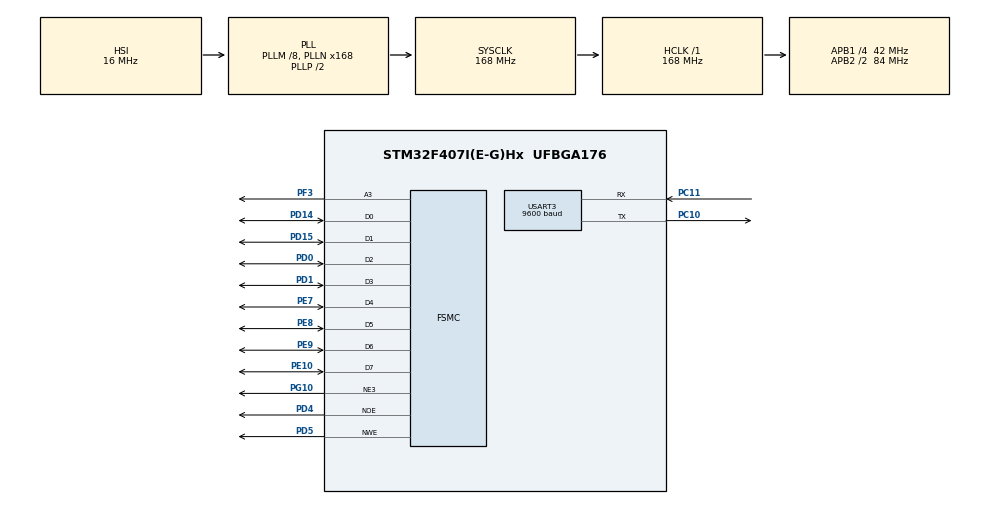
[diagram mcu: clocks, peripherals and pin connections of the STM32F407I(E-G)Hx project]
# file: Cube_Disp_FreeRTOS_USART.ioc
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FREERTOS.Tasks01=defaultTask,0,128,StartDefaultTask,Default,NULL,Dynamic,NULL,NULL
Mcu.Family=STM32F4
Mcu.Name=STM32F407I(E-G)Hx
Mcu.Package=UFBGA176
NVIC.PriorityGroup=NVIC_PRIORITYGROUP_4
NVIC.TIM1_UP_TIM10_IRQn=true\:0\:0\:false\:false\:true\:false\:false\:true
NVIC.TimeBase=TIM1_UP_TIM10_IRQn
NVIC.TimeBaseIP=TIM1
PC10.Mode=Asynchronous
PC10.Signal=USART3_TX
PC11.Mode=Asynchronous
PC11.Signal=USART3_RX
PD0.Signal=FSMC_D2_DA2
PD1.Signal=FSMC_D3_DA3
PD14.Signal=FSMC_D0_DA0
PD15.Signal=FSMC_D1_DA1
PD4.Signal=FSMC_NOE
PD5.Signal=FSMC_NWE
PE10.Signal=FSMC_D7_DA7
PE7.Signal=FSMC_D4_DA4
PE8.Signal=FSMC_D5_DA5
PE9.Signal=FSMC_D6_DA6
PF3.Signal=FSMC_A3
PG10.Mode=NorPsramChipSelect3_3
PG10.Signal=FSMC_NE3
ProjectManager.HeapSize=0x200
ProjectManager.StackSize=0x400
ProjectManager.TargetToolchain=SW4STM32
RCC.48MHZClocksFreq_Value=48000000
RCC.AHBFreq_Value=168000000
RCC.APB1CLKDivider=RCC_HCLK_DIV4
RCC.APB1Freq_Value=42000000
RCC.APB1TimFreq_Value=84000000
RCC.APB2CLKDivider=RCC_HCLK_DIV2
RCC.APB2Freq_Value=84000000
RCC.APB2TimFreq_Value=168000000
RCC.CortexFreq_Value=168000000
RCC.FLatency-AdvancedSettings=FLASH_LATENCY_5
RCC.HCLKFreq_Value=168000000
RCC.HSE_VALUE=25000000
RCC.HSI_VALUE=16000000
RCC.LSE_VALUE=32768
RCC.PLLM=8
RCC.PLLN=168
RCC.PLLQ=7
RCC.PWR_Regulator_Voltage_Scale-AdvancedSettings=PWR_REGULATOR_VOLTAGE_SCALE1
RCC.SYSCLKFreq_VALUE=168000000
RCC.SYSCLKSource=RCC_SYSCLKSOURCE_PLLCLK
RCC.VCOOutputFreq_Value=336000000
SH.FSMC_A3.0=FSMC_A3,A3_3
SH.FSMC_D0_DA0.0=FSMC_D0,8b-d3
SH.FSMC_D1_DA1.0=FSMC_D1,8b-d3
SH.FSMC_D2_DA2.0=FSMC_D2,8b-d3
SH.FSMC_D3_DA3.0=FSMC_D3,8b-d3
SH.FSMC_D4_DA4.0=FSMC_D4,8b-d3
SH.FSMC_D5_DA5.0=FSMC_D5,8b-d3
SH.FSMC_D6_DA6.0=FSMC_D6,8b-d3
SH.FSMC_D7_DA7.0=FSMC_D7,8b-d3
SH.FSMC_NOE.0=FSMC_NOE,Lcd3
SH.FSMC_NWE.0=FSMC_NWE,Lcd3
STMicroelectronics.X-CUBE-TOUCHGFX.4.13.0.ApplicationCcGraphicsJjApplication=TouchGFXOoGenerator
STMicroelectronics.X-CUBE-TOUCHGFX.4.13.0.tgfx_custom_height=240
STMicroelectronics.X-CUBE-TOUCHGFX.4.13.0.tgfx_custom_width=320
USART3.BaudRate=9600
USART3.Parity=PARITY_ODD
USART3.VirtualMode=VM_ASYNC
VP_CRC_VS_CRC.Mode=CRC_Activate
VP_FREERTOS_VS_CMSIS_V1.Mode=CMSIS_V1
VP_SYS_VS_tim1.Mode=TIM1
board=STM3240G-EVAL

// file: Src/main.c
/* USER CODE BEGIN Header */
/**
  ******************************************************************************
  * @file           : main.c
  * @brief          : Main program body
  ******************************************************************************
  * @attention
  *
  * <h2><center>&copy; Copyright (c) 2020 STMicroelectronics.
  * All rights reserved.</center></h2>
  *
  * This software component is licensed by ST under Ultimate Liberty license
  * SLA0044, the "License"; You may not use this file except in compliance with
  * the License. You may obtain a copy of the License at:
  *                             www.st.com/SLA0044
  *
  ******************************************************************************
  */
/* USER CODE END Header */

#include "main.h"
#include "cmsis_os.h"

/* USER CODE BEGIN Includes */
#include <stdio.h>
#ifdef __GNUC__
  /* With GCC, small printf (option LD Linker->Libraries->Small printf
     set to 'Yes') calls __io_putchar() */
  #define PUTCHAR_PROTOTYPE int __io_putchar(int ch)
#else
  #define PUTCHAR_PROTOTYPE int fputc(int ch, FILE *f)
#endif /* __GNUC__ */

/* USER CODE END Includes */

CRC_HandleTypeDef hcrc;

UART_HandleTypeDef huart3;

SRAM_HandleTypeDef hsram3;

osThreadId defaultTaskHandle;
/* USER CODE BEGIN PV */
/**
  * @brief  Retargets the C library printf function to the USART.
  * @param  None
  * @retval None
  */
PUTCHAR_PROTOTYPE
{
  /* Place your implementation of fputc here */
  /* e.g. write a character to the EVAL_COM1 and Loop until the end of transmission */
  HAL_UART_Transmit(&huart3, (uint8_t *)&ch, 1, 0xFFFF);

  return ch;
}
/* USER CODE END PV */

void SystemClock_Config(void);
static void MX_GPIO_Init(void);
static void MX_CRC_Init(void);
static void MX_FSMC_Init(void);
static void MX_USART3_UART_Init(void);
void StartDefaultTask(void const * argument);

int main(void)
{

  /* MCU Configuration--------------------------------------------------------*/

  /* Reset of all peripherals, Initializes the Flash interface and the Systick. */
  HAL_Init();

  /* Configure the system clock */
  SystemClock_Config();

  /* Initialize all configured peripherals */
  MX_GPIO_Init();
  MX_CRC_Init();
  MX_FSMC_Init();
  MX_USART3_UART_Init();
  /* USER CODE BEGIN 2 */
//  	 BSP_LCD_Init();
//  	 BSP_LCD_DisplayOn();
//  	BSP_LCD_Clear(LCD_COLOR_WHITE);
//  	BSP_LCD_DisplayStringAt(210, 100, "hello", LEFT_MODE);
  /* USER CODE END 2 */

  /* Create the thread(s) */
  /* definition and creation of defaultTask */
  osThreadDef(defaultTask, StartDefaultTask, osPriorityNormal, 0, 128);
  defaultTaskHandle = osThreadCreate(osThread(defaultTask), NULL);

  /* Start scheduler */
  osKernelStart();

  /* We should never get here as control is now taken by the scheduler */

  /* Infinite loop */
  while (1)
  {

  }
}

void SystemClock_Config(void)
{
  RCC_OscInitTypeDef RCC_OscInitStruct = {0};
  RCC_ClkInitTypeDef RCC_ClkInitStruct = {0};

  /** Configure the main internal regulator output voltage
  */
  __HAL_RCC_PWR_CLK_ENABLE();
  __HAL_PWR_VOLTAGESCALING_CONFIG(PWR_REGULATOR_VOLTAGE_SCALE1);
  /** Initializes the CPU, AHB and APB busses clocks
  */
  RCC_OscInitStruct.OscillatorType = RCC_OSCILLATORTYPE_HSI;
  RCC_OscInitStruct.HSIState = RCC_HSI_ON;
  RCC_OscInitStruct.HSICalibrationValue = RCC_HSICALIBRATION_DEFAULT;
  RCC_OscInitStruct.PLL.PLLState = RCC_PLL_ON;
  RCC_OscInitStruct.PLL.PLLSource = RCC_PLLSOURCE_HSI;
  RCC_OscInitStruct.PLL.PLLM = 8;
  RCC_OscInitStruct.PLL.PLLN = 168;
  RCC_OscInitStruct.PLL.PLLP = RCC_PLLP_DIV2;
  RCC_OscInitStruct.PLL.PLLQ = 7;
  if (HAL_RCC_OscConfig(&RCC_OscInitStruct) != HAL_OK)
  {
    Error_Handler();
  }
  /** Initializes the CPU, AHB and APB busses clocks
  */
  RCC_ClkInitStruct.ClockType = RCC_CLOCKTYPE_HCLK|RCC_CLOCKTYPE_SYSCLK
                              |RCC_CLOCKTYPE_PCLK1|RCC_CLOCKTYPE_PCLK2;
  RCC_ClkInitStruct.SYSCLKSource = RCC_SYSCLKSOURCE_PLLCLK;
  RCC_ClkInitStruct.AHBCLKDivider = RCC_SYSCLK_DIV1;
  RCC_ClkInitStruct.APB1CLKDivider = RCC_HCLK_DIV4;
  RCC_ClkInitStruct.APB2CLKDivider = RCC_HCLK_DIV2;

  if (HAL_RCC_ClockConfig(&RCC_ClkInitStruct, FLASH_LATENCY_5) != HAL_OK)
  {
    Error_Handler();
  }
}

static void MX_CRC_Init(void)
{

  hcrc.Instance = CRC;
  if (HAL_CRC_Init(&hcrc) != HAL_OK)
  {
    Error_Handler();
  }

}

static void MX_USART3_UART_Init(void)
{

  huart3.Instance = USART3;
  huart3.Init.BaudRate = 9600;
  huart3.Init.WordLength = UART_WORDLENGTH_8B;
  huart3.Init.StopBits = UART_STOPBITS_1;
  huart3.Init.Parity = UART_PARITY_ODD;
  huart3.Init.Mode = UART_MODE_TX_RX;
  huart3.Init.HwFlowCtl = UART_HWCONTROL_NONE;
  huart3.Init.OverSampling = UART_OVERSAMPLING_16;
  if (HAL_UART_Init(&huart3) != HAL_OK)
  {
    Error_Handler();
  }

}

static void MX_GPIO_Init(void)
{

  /* GPIO Ports Clock Enable */
  __HAL_RCC_GPIOG_CLK_ENABLE();
  __HAL_RCC_GPIOD_CLK_ENABLE();
  __HAL_RCC_GPIOC_CLK_ENABLE();
  __HAL_RCC_GPIOF_CLK_ENABLE();
  __HAL_RCC_GPIOE_CLK_ENABLE();

}

/* FSMC initialization function */
static void MX_FSMC_Init(void)
{

  FSMC_NORSRAM_TimingTypeDef Timing = {0};

  /** Perform the SRAM3 memory initialization sequence
  */
  hsram3.Instance = FSMC_NORSRAM_DEVICE;
  hsram3.Extended = FSMC_NORSRAM_EXTENDED_DEVICE;
  /* hsram3.Init */
  hsram3.Init.NSBank = FSMC_NORSRAM_BANK3;
  hsram3.Init.DataAddressMux = FSMC_DATA_ADDRESS_MUX_DISABLE;
  hsram3.Init.MemoryType = FSMC_MEMORY_TYPE_SRAM;
  hsram3.Init.MemoryDataWidth = FSMC_NORSRAM_MEM_BUS_WIDTH_8;
  hsram3.Init.BurstAccessMode = FSMC_BURST_ACCESS_MODE_DISABLE;
  hsram3.Init.WaitSignalPolarity = FSMC_WAIT_SIGNAL_POLARITY_LOW;
  hsram3.Init.WrapMode = FSMC_WRAP_MODE_DISABLE;
  hsram3.Init.WaitSignalActive = FSMC_WAIT_TIMING_BEFORE_WS;
  hsram3.Init.WriteOperation = FSMC_WRITE_OPERATION_ENABLE;
  hsram3.Init.WaitSignal = FSMC_WAIT_SIGNAL_DISABLE;
  hsram3.Init.ExtendedMode = FSMC_EXTENDED_MODE_DISABLE;
  hsram3.Init.AsynchronousWait = FSMC_ASYNCHRONOUS_WAIT_DISABLE;
  hsram3.Init.WriteBurst = FSMC_WRITE_BURST_DISABLE;
  hsram3.Init.PageSize = FSMC_PAGE_SIZE_NONE;
  /* Timing */
  Timing.AddressSetupTime = 15;
  Timing.AddressHoldTime = 15;
  Timing.DataSetupTime = 255;
  Timing.BusTurnAroundDuration = 15;
  Timing.CLKDivision = 16;
  Timing.DataLatency = 17;
  Timing.AccessMode = FSMC_ACCESS_MODE_A;
  /* ExtTiming */

  if (HAL_SRAM_Init(&hsram3, &Timing, NULL) != HAL_OK)
  {
    Error_Handler( );
  }

}

void StartDefaultTask(void const * argument)
{
  /* USER CODE BEGIN 5 */
  /* Infinite loop */
  for(;;)
  {
	printf("hello\n");
    osDelay(100);
  }
  /* USER CODE END 5 */
}

void HAL_TIM_PeriodElapsedCallback(TIM_HandleTypeDef *htim)
{
  if (htim->Instance == TIM1) {
    HAL_IncTick();
  }
}

void Error_Handler(void)
{
}

/************************ (C) COPYRIGHT STMicroelectronics *****END OF FILE****/
